# MOTOR register map
Registers are 32-bit, access not given, no defined reset value unless marked. A register's access mark holds for its fields unless they carry their own. Addresses are absolute; registers are grouped by the start of their names; [hi:lo] are bit positions; {n}, {i} and the like mark numbered series; 'fields as' and 'values as' point back to an identical list.

## TIMEBASE
{0x40069100+4i} TIMEBASE_{i}_0 (i=0..7)
  [15:0] TIMEBASE_COUNT_{i}_0
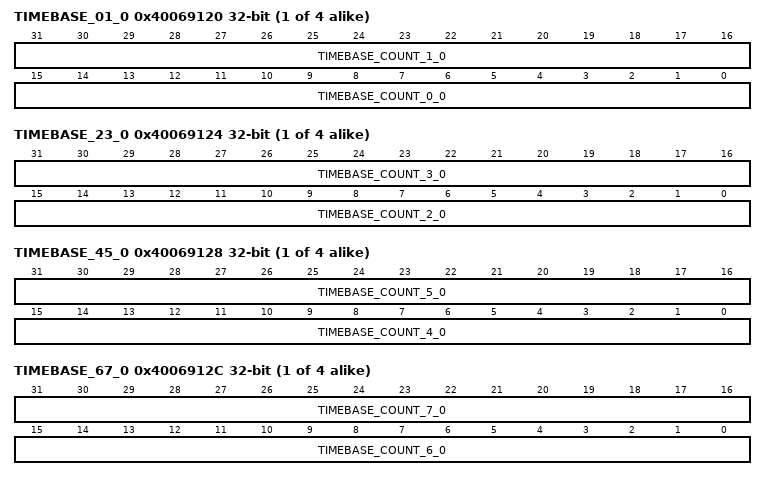
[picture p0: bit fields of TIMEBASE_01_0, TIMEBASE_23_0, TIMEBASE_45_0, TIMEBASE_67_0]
{0x40069120+0x400*i} TIMEBASE_01_{i} (i=0..3)
  [31:16] TIMEBASE_COUNT_1_{i}, [15:0] TIMEBASE_COUNT_0_{i}
{0x40069124+0x400*i} TIMEBASE_23_{i} (i=0..3)
  [31:16] TIMEBASE_COUNT_3_{i}, [15:0] TIMEBASE_COUNT_2_{i}
{0x40069128+0x400*i} TIMEBASE_45_{i} (i=0..3)
  [31:16] TIMEBASE_COUNT_5_{i}, [15:0] TIMEBASE_COUNT_4_{i}
{0x4006912C+0x400*i} TIMEBASE_67_{i} (i=0..3)
  [31:16] TIMEBASE_COUNT_7_{i}, [15:0] TIMEBASE_COUNT_6_{i}
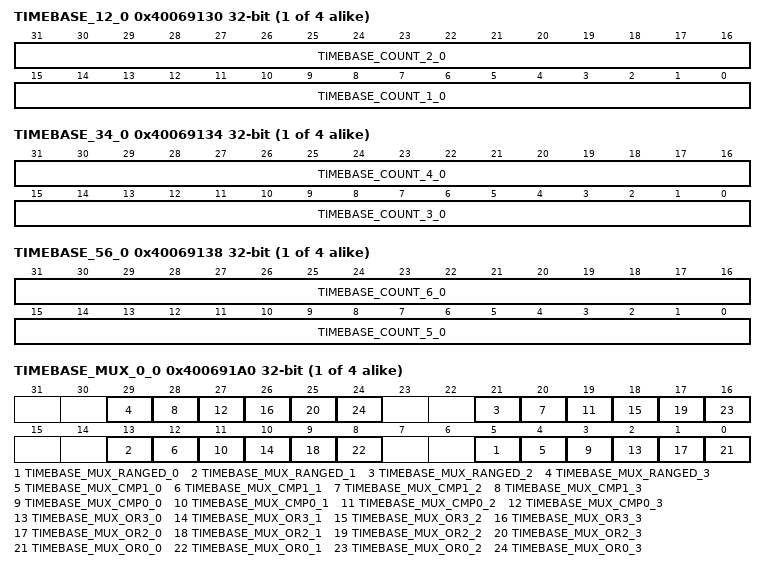
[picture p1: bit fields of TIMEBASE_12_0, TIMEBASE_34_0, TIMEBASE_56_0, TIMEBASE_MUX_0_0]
{0x40069130+0x400*i} TIMEBASE_12_{i} (i=0..3)
  [31:16] TIMEBASE_COUNT_2_{i}, [15:0] TIMEBASE_COUNT_1_{i}
{0x40069134+0x400*i} TIMEBASE_34_{i} (i=0..3)
  [31:16] TIMEBASE_COUNT_4_{i}, [15:0] TIMEBASE_COUNT_3_{i}
{0x40069138+0x400*i} TIMEBASE_56_{i} (i=0..3)
  [31:16] TIMEBASE_COUNT_6_{i}, [15:0] TIMEBASE_COUNT_5_{i}
{0x400691A0+0x400*i} TIMEBASE_MUX_0_{i} (i=0..3)
  [8n+5] TIMEBASE_MUX_RANGED_{n} (n=0..3), [8n+4] TIMEBASE_MUX_CMP1_{n} (n=0..3), [8n+3] TIMEBASE_MUX_CMP0_{n} (n=0..3), [8n+2] TIMEBASE_MUX_OR3_{n} (n=0..3), [8n+1] TIMEBASE_MUX_OR2_{n} (n=0..3), [8n] TIMEBASE_MUX_OR0_{n} (n=0..3)
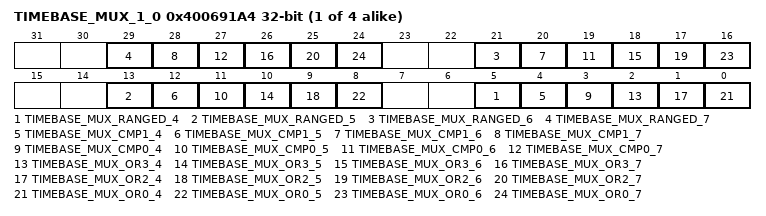
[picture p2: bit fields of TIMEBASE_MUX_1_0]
{0x400691A4+0x400*i} TIMEBASE_MUX_1_{i} (i=0..3)
  [8n-27] TIMEBASE_MUX_RANGED_{n} (n=4..7), [8n-28] TIMEBASE_MUX_CMP1_{n} (n=4..7), [8n-29] TIMEBASE_MUX_CMP0_{n} (n=4..7), [8n-30] TIMEBASE_MUX_OR3_{n} (n=4..7), [8n-31] TIMEBASE_MUX_OR2_{n} (n=4..7), [8n-32] TIMEBASE_MUX_OR0_{n} (n=4..7)
{0x40069500+4i} TIMEBASE_{i}_1 (i=0..7)
  [15:0] TIMEBASE_COUNT_{i}_1
{0x40069900+4i} TIMEBASE_{i}_2 (i=0..7)
  [15:0] TIMEBASE_COUNT_{i}_2
{0x40069D00+4i} TIMEBASE_{i}_3 (i=0..7)
  [15:0] TIMEBASE_COUNT_{i}_3

## SCALEVALUE
{0x40069140+4i} SCALEVALUE_{i}_0 (i=0..7)
  [7:0] SCALEVALUE_{i}_0
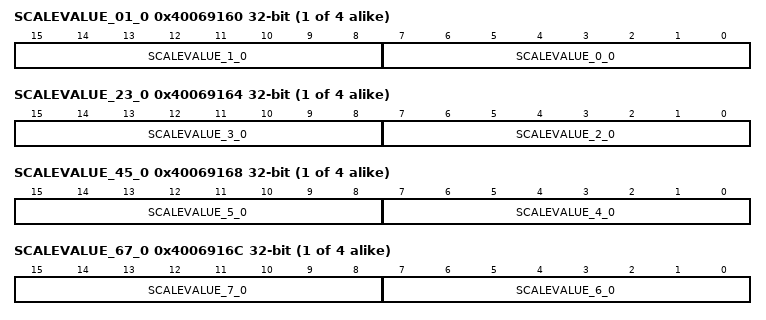
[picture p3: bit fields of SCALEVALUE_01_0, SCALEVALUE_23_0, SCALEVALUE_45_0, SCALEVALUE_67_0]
{0x40069160+0x400*i} SCALEVALUE_01_{i} (i=0..3)
  [15:8] SCALEVALUE_1_{i}, [7:0] SCALEVALUE_0_{i}
{0x40069164+0x400*i} SCALEVALUE_23_{i} (i=0..3)
  [15:8] SCALEVALUE_3_{i}, [7:0] SCALEVALUE_2_{i}
{0x40069168+0x400*i} SCALEVALUE_45_{i} (i=0..3)
  [15:8] SCALEVALUE_5_{i}, [7:0] SCALEVALUE_4_{i}
{0x4006916C+0x400*i} SCALEVALUE_67_{i} (i=0..3)
  [15:8] SCALEVALUE_7_{i}, [7:0] SCALEVALUE_6_{i}
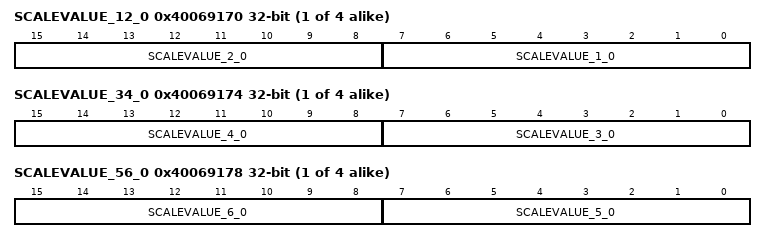
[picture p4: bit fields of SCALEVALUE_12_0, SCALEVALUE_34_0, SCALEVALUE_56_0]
{0x40069170+0x400*i} SCALEVALUE_12_{i} (i=0..3)
  [15:8] SCALEVALUE_2_{i}, [7:0] SCALEVALUE_1_{i}
{0x40069174+0x400*i} SCALEVALUE_34_{i} (i=0..3)
  [15:8] SCALEVALUE_4_{i}, [7:0] SCALEVALUE_3_{i}
{0x40069178+0x400*i} SCALEVALUE_56_{i} (i=0..3)
  [15:8] SCALEVALUE_6_{i}, [7:0] SCALEVALUE_5_{i}
{0x40069540+4i} SCALEVALUE_{i}_1 (i=0..7)
  [7:0] SCALEVALUE_{i}_1
{0x40069940+4i} SCALEVALUE_{i}_2 (i=0..7)
  [7:0] SCALEVALUE_{i}_2
{0x40069D40+4i} SCALEVALUE_{i}_3 (i=0..7)
  [7:0] SCALEVALUE_{i}_3

## HWSTORE
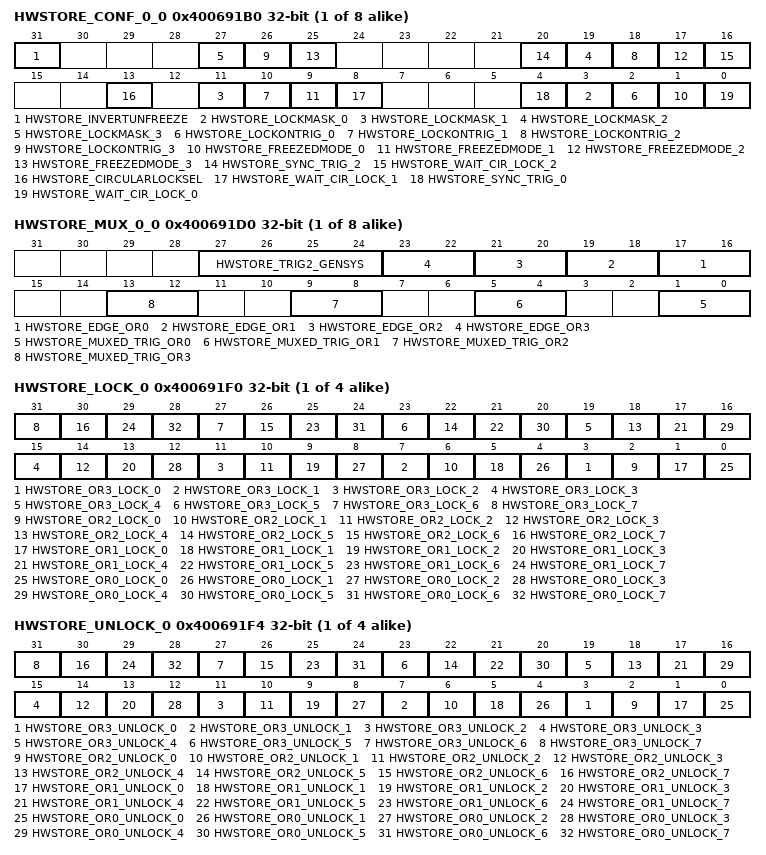
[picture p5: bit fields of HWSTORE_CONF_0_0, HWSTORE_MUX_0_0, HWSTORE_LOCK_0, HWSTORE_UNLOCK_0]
{0x400691B0+4i} HWSTORE_CONF_{i}_0 (i=0..7)
  [31] HWSTORE_INVERTUNFREEZE, [8n+3] HWSTORE_LOCKMASK_{n} (n=0..3), [8n+2] HWSTORE_LOCKONTRIG_{n} (n=0..3), [8n+1] HWSTORE_FREEZEDMODE_{n} (n=0..3), [20] HWSTORE_SYNC_TRIG_2, [16] HWSTORE_WAIT_CIR_LOCK_2, [13] HWSTORE_CIRCULARLOCKSEL, [8] HWSTORE_WAIT_CIR_LOCK_1, [4] HWSTORE_SYNC_TRIG_0, [0] HWSTORE_WAIT_CIR_LOCK_0
{0x400691D0+4i} HWSTORE_MUX_{i}_0 (i=0..7)
  [27:24] HWSTORE_TRIG2_GENSYS, [2n+17:2n+16] HWSTORE_EDGE_OR{n} (n=0..3), [4n+1:4n] HWSTORE_MUXED_TRIG_OR{n} (n=0..3)
{0x400691F0+0x400*i} HWSTORE_LOCK_{i} (i=0..3)
  [4n+3] HWSTORE_OR3_LOCK_{n} (n=0..7), [4n+2] HWSTORE_OR2_LOCK_{n} (n=0..7), [4n+1] HWSTORE_OR1_LOCK_{n} (n=0..7), [4n] HWSTORE_OR0_LOCK_{n} (n=0..7)
{0x400691F4+0x400*i} HWSTORE_UNLOCK_{i} wo (i=0..3)
  [4n+3] HWSTORE_OR3_UNLOCK_{n} (n=0..7), [4n+2] HWSTORE_OR2_UNLOCK_{n} (n=0..7), [4n+1] HWSTORE_OR1_UNLOCK_{n} (n=0..7), [4n] HWSTORE_OR0_UNLOCK_{n} (n=0..7)
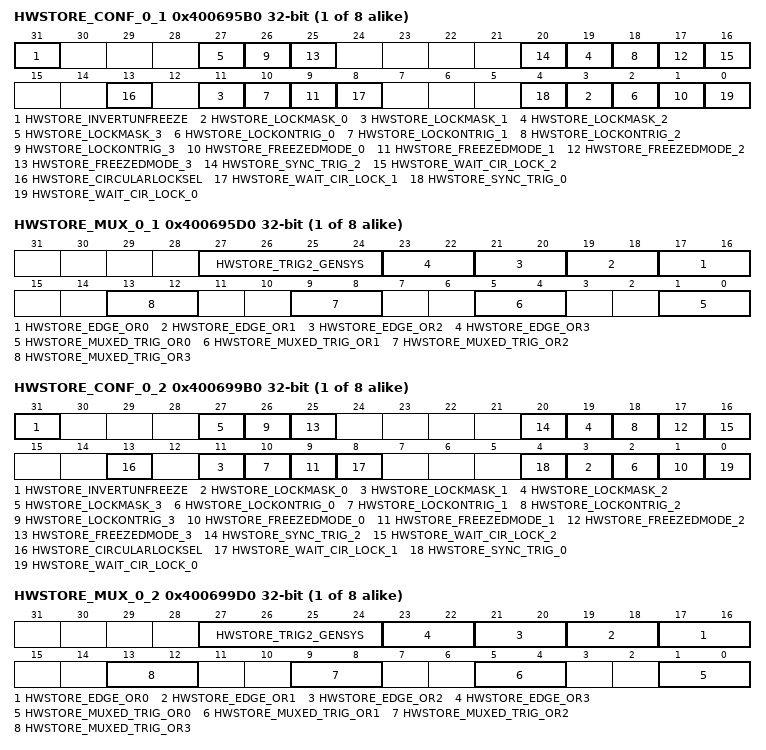
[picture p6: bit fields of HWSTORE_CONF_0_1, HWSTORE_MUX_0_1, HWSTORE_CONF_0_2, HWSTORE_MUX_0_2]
{0x400695B0+4i} HWSTORE_CONF_{i}_1 (i=0..7)
  fields as HWSTORE_CONF_0_0
{0x400695D0+4i} HWSTORE_MUX_{i}_1 (i=0..7)
  fields as HWSTORE_MUX_0_0
{0x400699B0+4i} HWSTORE_CONF_{i}_2 (i=0..7)
  fields as HWSTORE_CONF_0_0
{0x400699D0+4i} HWSTORE_MUX_{i}_2 (i=0..7)
  fields as HWSTORE_MUX_0_0
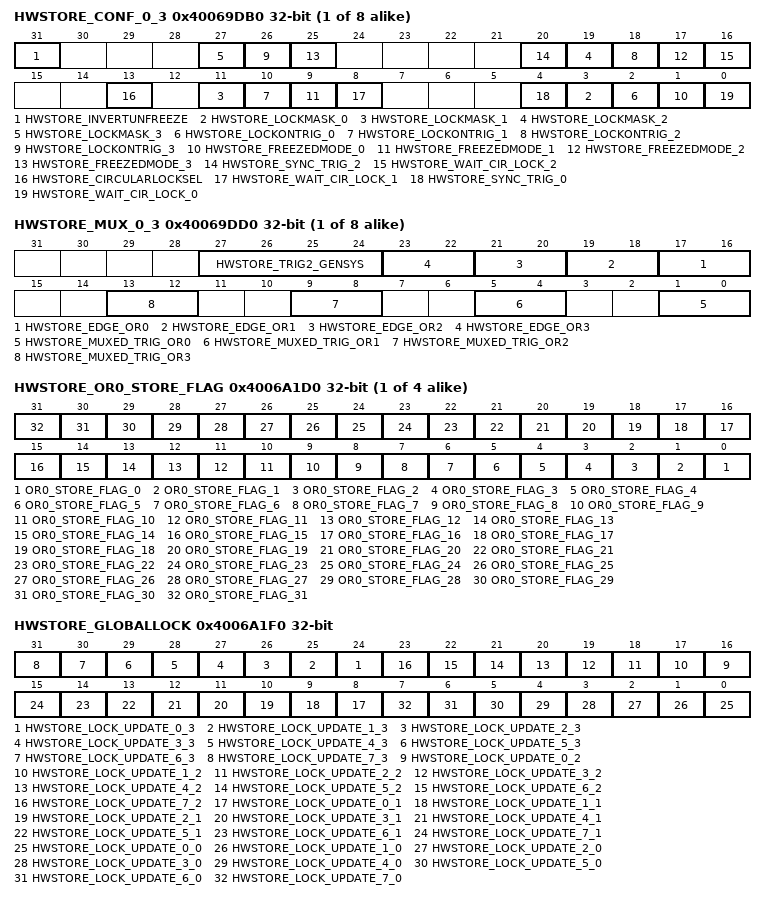
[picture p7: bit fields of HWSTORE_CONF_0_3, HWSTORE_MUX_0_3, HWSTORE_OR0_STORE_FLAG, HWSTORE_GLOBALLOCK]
{0x40069DB0+4i} HWSTORE_CONF_{i}_3 (i=0..7)
  fields as HWSTORE_CONF_0_0
{0x40069DD0+4i} HWSTORE_MUX_{i}_3 (i=0..7)
  fields as HWSTORE_MUX_0_0
{0x4006A1D0+4i} HWSTORE_OR{i}_STORE_FLAG (i=0..3)
  [n] OR{i}_STORE_FLAG_{n} (n=0..31)
0x4006A1F0 HWSTORE_GLOBALLOCK
  [n+24] HWSTORE_LOCK_UPDATE_{n}_3 (n=0..7), [n+16] HWSTORE_LOCK_UPDATE_{n}_2 (n=0..7), [n+8] HWSTORE_LOCK_UPDATE_{n}_1 (n=0..7), [n] HWSTORE_LOCK_UPDATE_{n}_0 (n=0..7)
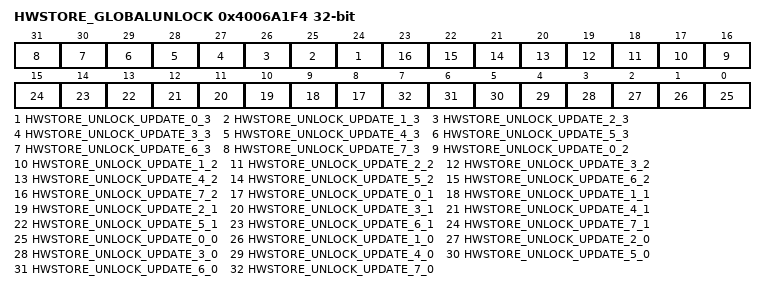
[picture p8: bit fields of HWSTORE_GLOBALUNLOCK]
0x4006A1F4 HWSTORE_GLOBALUNLOCK wo
  [n+24] HWSTORE_UNLOCK_UPDATE_{n}_3 (n=0..7), [n+16] HWSTORE_UNLOCK_UPDATE_{n}_2 (n=0..7), [n+8] HWSTORE_UNLOCK_UPDATE_{n}_1 (n=0..7), [n] HWSTORE_UNLOCK_UPDATE_{n}_0 (n=0..7)
